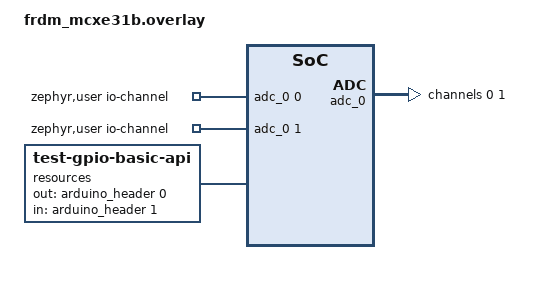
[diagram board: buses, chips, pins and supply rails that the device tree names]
/*
 * Copyright 2025 NXP
 *
 * SPDX-License-Identifier: Apache-2.0
 */

/* Add test label to edma node */
tst_dma0: &edma {};

#include <zephyr/dt-bindings/adc/adc.h>

/ {
	zephyr,user {
		io-channels = <&adc_0 0>, <&adc_0 1>;
	};
};

&adc_0 {
	#address-cells = <1>;
	#size-cells = <0>;
	channel@0 {
		reg = <0>;
		zephyr,gain = "ADC_GAIN_1";
		zephyr,reference = "ADC_REF_VDD_1";
		zephyr,vref-mv = <3300>;
		zephyr,acquisition-time = <ADC_ACQ_TIME_DEFAULT>;
		zephyr,resolution = <15>;
		zephyr,input-positive = <48>;
	};
	channel@1 {
		reg = <0x1>;
		zephyr,gain = "ADC_GAIN_1";
		zephyr,reference = "ADC_REF_VDD_1";
		zephyr,vref-mv = <3300>;
		zephyr,acquisition-time = <ADC_ACQ_TIME_DEFAULT>;
		zephyr,resolution = <15>;
		zephyr,input-positive = <55>;
	};
};

/ {
	resources {
		compatible = "test-gpio-basic-api";
		status = "okay";
		out-gpios = <&arduino_header 0 (GPIO_ACTIVE_HIGH | GPIO_PUSH_PULL | GPIO_PULL_UP)>;
		in-gpios = <&arduino_header 1 (GPIO_ACTIVE_HIGH | GPIO_PUSH_PULL | GPIO_PULL_UP)>;
	};
};

&gpioe_l {
	status = "okay";
};

&gpioe_h {
	status = "okay";
};

&eirq0_default {
	group2 {
		pinmux = <PTE15_EIRQ14>;
		input-enable;
	};
};
